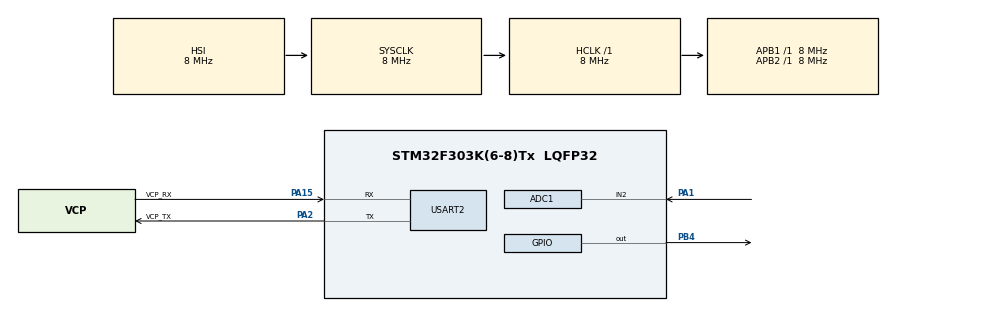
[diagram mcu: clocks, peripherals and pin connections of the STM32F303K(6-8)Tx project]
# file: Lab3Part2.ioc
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ADC1.Channel-0\#ChannelRegularConversion=ADC_CHANNEL_2
ADC1.ContinuousConvMode=ENABLE
ADC1.DMAContinuousRequests=ENABLE
ADC1.NbrOfConversionFlag=1
ADC1.Offset-0\#ChannelRegularConversion=0
ADC1.OffsetNumber-0\#ChannelRegularConversion=ADC_OFFSET_NONE
ADC1.Rank-0\#ChannelRegularConversion=1
ADC1.SamplingTime-0\#ChannelRegularConversion=ADC_SAMPLETIME_1CYCLE_5
ADC1.SamplingTimeOPAMP-0\#ChannelRegularConversion=ADC_SAMPLETIME_4CYCLES_5
ADC1.SubFamily=STM32F303x8
ADC1.master=1
Dma.ADC1.0.Direction=DMA_PERIPH_TO_MEMORY
Dma.ADC1.0.Instance=DMA1_Channel1
Dma.ADC1.0.MemDataAlignment=DMA_MDATAALIGN_HALFWORD
Dma.ADC1.0.MemInc=DMA_MINC_ENABLE
Dma.ADC1.0.Mode=DMA_CIRCULAR
Dma.ADC1.0.PeriphDataAlignment=DMA_PDATAALIGN_HALFWORD
Dma.ADC1.0.PeriphInc=DMA_PINC_DISABLE
Dma.ADC1.0.Priority=DMA_PRIORITY_LOW
Dma.Request0=ADC1
Mcu.Family=STM32F3
Mcu.Name=STM32F303K(6-8)Tx
Mcu.Package=LQFP32
NVIC.DMA1_Channel1_IRQn=true\:0\:0\:false\:false\:true\:false\:true\:true
NVIC.PriorityGroup=NVIC_PRIORITYGROUP_4
PA1.Mode=IN2-Single-Ended
PA1.Signal=ADC1_IN2
PA13.GPIO_Label=SWDIO
PA13.Mode=Serial_Wire
PA13.Signal=SYS_JTMS-SWDIO
PA14.GPIO_Label=SWCLK
PA14.Mode=Serial_Wire
PA14.Signal=SYS_JTCK-SWCLK
PA15.GPIO_Label=VCP_RX
PA15.Mode=Asynchronous
PA15.Signal=USART2_RX
PA2.GPIO_Label=VCP_TX
PA2.Mode=Asynchronous
PA2.Signal=USART2_TX
PB4.Signal=GPIO_Output
PF0\ /\ OSC_IN.GPIO_Label=MCO
PF0\ /\ OSC_IN.Mode=HSE-External-Clock-Source
PF0\ /\ OSC_IN.Signal=RCC_OSC_IN
ProjectManager.HeapSize=0x200
ProjectManager.StackSize=0x400
ProjectManager.TargetToolchain=STM32CubeIDE
RCC.AHBFreq_Value=8000000
RCC.APB1Freq_Value=8000000
RCC.APB2Freq_Value=8000000
RCC.CortexFreq_Value=8000000
RCC.HSE_VALUE=8000000
RCC.HSI_VALUE=8000000
RCC.SYSCLKFreq_VALUE=8000000
USART2.VirtualMode-Asynchronous=VM_ASYNC
board=NUCLEO-F303K8

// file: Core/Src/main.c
/* USER CODE BEGIN Header */
/**
  ******************************************************************************
  * @file           : main.c
  * @brief          : Main program body
  ******************************************************************************
  * @attention
  *
  * Copyright (c) 2024 STMicroelectronics.
  * All rights reserved.
  *
  * This software is licensed under terms that can be found in the LICENSE file
  * in the root directory of this software component.
  * If no LICENSE file comes with this software, it is provided AS-IS.
  *
  ******************************************************************************
  */
/* USER CODE END Header */
#include "main.h"

ADC_HandleTypeDef hadc1;
DMA_HandleTypeDef hdma_adc1;

UART_HandleTypeDef huart2;

void SystemClock_Config(void);
static void MX_GPIO_Init(void);
static void MX_DMA_Init(void);
static void MX_USART2_UART_Init(void);
static void MX_ADC1_Init(void);

/* USER CODE BEGIN 0 */
uint16_t adc_buf[1024];
/* USER CODE END 0 */

int main(void)
{

  /* MCU Configuration--------------------------------------------------------*/

  /* Reset of all peripherals, Initializes the Flash interface and the Systick. */
  HAL_Init();

  /* Configure the system clock */
  SystemClock_Config();

  /* Initialize all configured peripherals */
  MX_GPIO_Init();
  MX_DMA_Init();
  MX_USART2_UART_Init();
  MX_ADC1_Init();
  /* USER CODE BEGIN 2 */
  HAL_ADC_Start_DMA(&hadc1, (uint32_t*)adc_buf, 1024);
  /* USER CODE END 2 */

  /* Infinite loop */
  while (1)
  {

  }
}

void SystemClock_Config(void)
{
  RCC_OscInitTypeDef RCC_OscInitStruct = {0};
  RCC_ClkInitTypeDef RCC_ClkInitStruct = {0};
  RCC_PeriphCLKInitTypeDef PeriphClkInit = {0};

  /** Initializes the RCC Oscillators according to the specified parameters
  * in the RCC_OscInitTypeDef structure.
  */
  RCC_OscInitStruct.OscillatorType = RCC_OSCILLATORTYPE_HSI;
  RCC_OscInitStruct.HSIState = RCC_HSI_ON;
  RCC_OscInitStruct.HSICalibrationValue = RCC_HSICALIBRATION_DEFAULT;
  RCC_OscInitStruct.PLL.PLLState = RCC_PLL_ON;
  RCC_OscInitStruct.PLL.PLLSource = RCC_PLLSOURCE_HSI;
  RCC_OscInitStruct.PLL.PLLMUL = RCC_PLL_MUL2;
  if (HAL_RCC_OscConfig(&RCC_OscInitStruct) != HAL_OK)
  {
    Error_Handler();
  }

  /** Initializes the CPU, AHB and APB buses clocks
  */
  RCC_ClkInitStruct.ClockType = RCC_CLOCKTYPE_HCLK|RCC_CLOCKTYPE_SYSCLK
                              |RCC_CLOCKTYPE_PCLK1|RCC_CLOCKTYPE_PCLK2;
  RCC_ClkInitStruct.SYSCLKSource = RCC_SYSCLKSOURCE_HSI;
  RCC_ClkInitStruct.AHBCLKDivider = RCC_SYSCLK_DIV1;
  RCC_ClkInitStruct.APB1CLKDivider = RCC_HCLK_DIV1;
  RCC_ClkInitStruct.APB2CLKDivider = RCC_HCLK_DIV1;

  if (HAL_RCC_ClockConfig(&RCC_ClkInitStruct, FLASH_LATENCY_0) != HAL_OK)
  {
    Error_Handler();
  }
  PeriphClkInit.PeriphClockSelection = RCC_PERIPHCLK_ADC12;
  PeriphClkInit.Adc12ClockSelection = RCC_ADC12PLLCLK_DIV1;
  if (HAL_RCCEx_PeriphCLKConfig(&PeriphClkInit) != HAL_OK)
  {
    Error_Handler();
  }
}

static void MX_ADC1_Init(void)
{

  ADC_MultiModeTypeDef multimode = {0};
  ADC_ChannelConfTypeDef sConfig = {0};

  /** Common config
  */
  hadc1.Instance = ADC1;
  hadc1.Init.ClockPrescaler = ADC_CLOCK_ASYNC_DIV1;
  hadc1.Init.Resolution = ADC_RESOLUTION_12B;
  hadc1.Init.ScanConvMode = ADC_SCAN_DISABLE;
  hadc1.Init.ContinuousConvMode = ENABLE;
  hadc1.Init.DiscontinuousConvMode = DISABLE;
  hadc1.Init.ExternalTrigConvEdge = ADC_EXTERNALTRIGCONVEDGE_NONE;
  hadc1.Init.ExternalTrigConv = ADC_SOFTWARE_START;
  hadc1.Init.DataAlign = ADC_DATAALIGN_RIGHT;
  hadc1.Init.NbrOfConversion = 1;
  hadc1.Init.DMAContinuousRequests = ENABLE;
  hadc1.Init.EOCSelection = ADC_EOC_SINGLE_CONV;
  hadc1.Init.LowPowerAutoWait = DISABLE;
  hadc1.Init.Overrun = ADC_OVR_DATA_OVERWRITTEN;
  if (HAL_ADC_Init(&hadc1) != HAL_OK)
  {
    Error_Handler();
  }

  /** Configure the ADC multi-mode
  */
  multimode.Mode = ADC_MODE_INDEPENDENT;
  if (HAL_ADCEx_MultiModeConfigChannel(&hadc1, &multimode) != HAL_OK)
  {
    Error_Handler();
  }

  /** Configure Regular Channel
  */
  sConfig.Channel = ADC_CHANNEL_2;
  sConfig.Rank = ADC_REGULAR_RANK_1;
  sConfig.SingleDiff = ADC_SINGLE_ENDED;
  sConfig.SamplingTime = ADC_SAMPLETIME_1CYCLE_5;
  sConfig.OffsetNumber = ADC_OFFSET_NONE;
  sConfig.Offset = 0;
  if (HAL_ADC_ConfigChannel(&hadc1, &sConfig) != HAL_OK)
  {
    Error_Handler();
  }

}

static void MX_USART2_UART_Init(void)
{

  huart2.Instance = USART2;
  huart2.Init.BaudRate = 38400;
  huart2.Init.WordLength = UART_WORDLENGTH_8B;
  huart2.Init.StopBits = UART_STOPBITS_1;
  huart2.Init.Parity = UART_PARITY_NONE;
  huart2.Init.Mode = UART_MODE_TX_RX;
  huart2.Init.HwFlowCtl = UART_HWCONTROL_NONE;
  huart2.Init.OverSampling = UART_OVERSAMPLING_16;
  huart2.Init.OneBitSampling = UART_ONE_BIT_SAMPLE_DISABLE;
  huart2.AdvancedInit.AdvFeatureInit = UART_ADVFEATURE_NO_INIT;
  if (HAL_UART_Init(&huart2) != HAL_OK)
  {
    Error_Handler();
  }

}

static void MX_DMA_Init(void)
{

  /* DMA controller clock enable */
  __HAL_RCC_DMA1_CLK_ENABLE();

  /* DMA interrupt init */
  /* DMA1_Channel1_IRQn interrupt configuration */
  HAL_NVIC_SetPriority(DMA1_Channel1_IRQn, 0, 0);
  HAL_NVIC_EnableIRQ(DMA1_Channel1_IRQn);

}

static void MX_GPIO_Init(void)
{
  GPIO_InitTypeDef GPIO_InitStruct = {0};

  /* GPIO Ports Clock Enable */
  __HAL_RCC_GPIOF_CLK_ENABLE();
  __HAL_RCC_GPIOA_CLK_ENABLE();
  __HAL_RCC_GPIOB_CLK_ENABLE();

  /*Configure GPIO pin Output Level */
  HAL_GPIO_WritePin(GPIOB, GPIO_PIN_4, GPIO_PIN_RESET);

  /*Configure GPIO pin : PB4 */
  GPIO_InitStruct.Pin = GPIO_PIN_4;
  GPIO_InitStruct.Mode = GPIO_MODE_OUTPUT_PP;
  GPIO_InitStruct.Pull = GPIO_NOPULL;
  GPIO_InitStruct.Speed = GPIO_SPEED_FREQ_LOW;
  HAL_GPIO_Init(GPIOB, &GPIO_InitStruct);

}

/* USER CODE BEGIN 4 */
void HAL_ADC_ConvHalfCpltCallback(ADC_HandleTypeDef* hadc) {
HAL_GPIO_WritePin(GPIOB, GPIO_PIN_4, GPIO_PIN_SET);
}
// Called when buffer is completely filled
void HAL_ADC_ConvCpltCallback(ADC_HandleTypeDef* hadc) {
HAL_GPIO_WritePin(GPIOB, GPIO_PIN_4, GPIO_PIN_RESET);
}

/* USER CODE END 4 */

void Error_Handler(void)
{
  __disable_irq();
  while (1)
  {
  }
}
